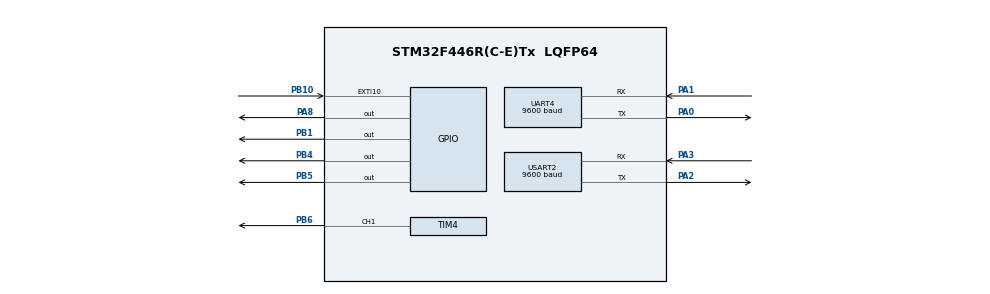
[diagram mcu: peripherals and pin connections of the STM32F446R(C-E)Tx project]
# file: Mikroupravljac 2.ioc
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Mcu.Family=STM32F4
Mcu.Name=STM32F446R(C-E)Tx
Mcu.Package=LQFP64
NVIC.EXTI15_10_IRQn=true\:3\:0\:true\:false\:true\:true\:true\:true
NVIC.PriorityGroup=NVIC_PRIORITYGROUP_4
NVIC.USART2_IRQn=true\:0\:0\:false\:false\:true\:true\:true\:true
PA0-WKUP.Mode=Asynchronous
PA0-WKUP.Signal=UART4_TX
PA1.Mode=Asynchronous
PA1.Signal=UART4_RX
PA13.Mode=Serial_Wire
PA13.Signal=SYS_JTMS-SWDIO
PA14.Mode=Serial_Wire
PA14.Signal=SYS_JTCK-SWCLK
PA2.Mode=Asynchronous
PA2.Signal=USART2_TX
PA3.Mode=Asynchronous
PA3.Signal=USART2_RX
PA8.Signal=GPIO_Output
PB1.Signal=GPIO_Output
PB10.GPIO_ModeDefaultEXTI=GPIO_MODE_IT_FALLING
PB10.GPIO_PuPd=GPIO_PULLUP
PB10.Signal=GPXTI10
PB4.Signal=GPIO_Output
PB5.Signal=GPIO_Output
PB6.Signal=S_TIM4_CH1
ProjectManager.HeapSize=0x200
ProjectManager.StackSize=0x400
ProjectManager.TargetToolchain=STM32CubeIDE
RCC.CortexFreq_Value=16000000
RCC.USBFreq_Value=96000000
RCC.VCOOutputFreq_Value=192000000
SH.S_TIM4_CH1.0=TIM4_CH1,PWM Generation1 CH1
TIM4.Channel-PWM\ Generation1\ CH1=TIM_CHANNEL_1
TIM4.Period=2999
TIM4.Prescaler=15999
TIM4.Pulse-PWM\ Generation1\ CH1=1500
UART4.BaudRate=9600
UART4.VirtualMode=Asynchronous
USART2.BaudRate=9600
USART2.VirtualMode=VM_ASYNC
board=custom

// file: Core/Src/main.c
/* USER CODE BEGIN Header */
/**
  ******************************************************************************
  * @file           : main.c
  * @brief          : Main program body
  ******************************************************************************
  * @attention
  *
  * Copyright (c) 2025 STMicroelectronics.
  * All rights reserved.
  *
  * This software is licensed under terms that can be found in the LICENSE file
  * in the root directory of this software component.
  * If no LICENSE file comes with this software, it is provided AS-IS.
  *
  ******************************************************************************
  */
/* USER CODE END Header */
#include "main.h"
#include "tim.h"
#include "usart.h"
#include "gpio.h"

void SystemClock_Config(void);

int main(void)
{

  /* MCU Configuration--------------------------------------------------------*/

  /* Reset of all peripherals, Initializes the Flash interface and the Systick. */
  HAL_Init();

  /* Configure the system clock */
  SystemClock_Config();

  /* Initialize all configured peripherals */
  MX_GPIO_Init();
  MX_USART2_UART_Init();
  MX_UART4_Init();
  MX_TIM4_Init();
  /* USER CODE BEGIN 2 */
  //int status = 0;
  int status = 0;
  uint8_t msgt = 0x0, msgr = 0x0;
  /* USER CODE END 2 */

  /* Infinite loop */
  /* USER CODE BEGIN WHILE */
  while (1)
  {
	  switch(status) {
	  	  case 0:	//slucaj greske, titrajuce zuto
	  		  __HAL_TIM_SET_COMPARE(&htim4, TIM_CHANNEL_1, 1500);
	  	  	  HAL_TIM_PWM_Start(&htim4, TIM_CHANNEL_1);
	  		  HAL_GPIO_WritePin(GPIOA, GPIO_PIN_8, 0);	//gasenje svega osim zutog
	  		  HAL_GPIO_WritePin(GPIOB, GPIO_PIN_1|GPIO_PIN_4|GPIO_PIN_5, 0);	//^
			  HAL_Delay(3000);
	  		  break;

	  	  case 1:	//Zeleno za aute
	  		  if(msgt!=0x0){
	  	  		  __HAL_TIM_SET_COMPARE(&htim4, TIM_CHANNEL_1, 3000);
	  			  HAL_TIM_PWM_Stop(&htim4, TIM_CHANNEL_1);
	  			  HAL_GPIO_WritePin(GPIOA, GPIO_PIN_8, 1);	//zeleno za aute
	  			  HAL_GPIO_WritePin(GPIOB, GPIO_PIN_5, 1);	//crveno za pješake
	  			  HAL_GPIO_WritePin(GPIOB, GPIO_PIN_1|GPIO_PIN_4, 0);

	  		  }
	  			  break;

	  	  case 2:	//Zeleno za pjesake
	  		  HAL_TIM_PWM_Stop(&htim4, TIM_CHANNEL_1);
	  		  __HAL_TIM_SET_COMPARE(&htim4, TIM_CHANNEL_1, 3000);
	  		  HAL_TIM_PWM_Start(&htim4, TIM_CHANNEL_1);		//upaljeno zuto 3s prije promjene na crveno
	  		  HAL_GPIO_WritePin(GPIOA, GPIO_PIN_8, 0);		//gasi zeleno za aute
			  HAL_Delay(3000);
			  HAL_GPIO_WritePin(GPIOB, GPIO_PIN_5, 0);		//gasi crveno za pjesake
	  		  HAL_GPIO_WritePin(GPIOB, GPIO_PIN_1|GPIO_PIN_4, 1);	//zeleno pjesaci i crveno auti
	  		  HAL_TIM_PWM_Stop(&htim4, TIM_CHANNEL_1);
	  		  HAL_Delay(20000);		//20s za prijelaz pjesaka
	 		  HAL_TIM_PWM_Start(&htim4, TIM_CHANNEL_1);
	 		  HAL_GPIO_WritePin(GPIOB, GPIO_PIN_1, 0);	//gasimo zeleno pjesake
  			  HAL_GPIO_WritePin(GPIOB, GPIO_PIN_5, 1);	//crveno za pjesake
  			  HAL_Delay(3000);		//3s zutog prije promjene
  			  HAL_TIM_PWM_Stop(&htim4, TIM_CHANNEL_1);
	  		  __HAL_TIM_SET_COMPARE(&htim4, TIM_CHANNEL_1, 1500);	//Vracanje PWM Duty cyclea za titranje
	  		  HAL_GPIO_WritePin(GPIOA, GPIO_PIN_8, 1);	//zeleno za aute
	  		  HAL_GPIO_WritePin(GPIOB, GPIO_PIN_1|GPIO_PIN_4, 0);
			  status = 1;
	  		  break;
	  	  }
	  	  msgt = 0x0;
	  	  msgr = 0x4;
	  	  HAL_UART_Receive(&huart4, &msgr, sizeof(msgr), 1000);	//primanje podatka
	  	  HAL_Delay(20);

	  	  if(msgr != 0x0){
	  		 msgt = msgr;
	  		 HAL_UART_Transmit(&huart4, &msgt, sizeof(msgt), 100);	//slanje odgovora
	  		 status = 1;
	  	  }else{
	  		 status = 0;

	  	  }
	  	  if(msgr == 0x6){
	  		  status = 2;
	  	  }

  	  }
}

void SystemClock_Config(void)
{
  RCC_OscInitTypeDef RCC_OscInitStruct = {0};
  RCC_ClkInitTypeDef RCC_ClkInitStruct = {0};

  /** Configure the main internal regulator output voltage
  */
  __HAL_RCC_PWR_CLK_ENABLE();
  __HAL_PWR_VOLTAGESCALING_CONFIG(PWR_REGULATOR_VOLTAGE_SCALE3);

  /** Initializes the RCC Oscillators according to the specified parameters
  * in the RCC_OscInitTypeDef structure.
  */
  RCC_OscInitStruct.OscillatorType = RCC_OSCILLATORTYPE_HSI;
  RCC_OscInitStruct.HSIState = RCC_HSI_ON;
  RCC_OscInitStruct.HSICalibrationValue = RCC_HSICALIBRATION_DEFAULT;
  RCC_OscInitStruct.PLL.PLLState = RCC_PLL_NONE;
  if (HAL_RCC_OscConfig(&RCC_OscInitStruct) != HAL_OK)
  {
    Error_Handler();
  }

  /** Initializes the CPU, AHB and APB buses clocks
  */
  RCC_ClkInitStruct.ClockType = RCC_CLOCKTYPE_HCLK|RCC_CLOCKTYPE_SYSCLK
                              |RCC_CLOCKTYPE_PCLK1|RCC_CLOCKTYPE_PCLK2;
  RCC_ClkInitStruct.SYSCLKSource = RCC_SYSCLKSOURCE_HSI;
  RCC_ClkInitStruct.AHBCLKDivider = RCC_SYSCLK_DIV1;
  RCC_ClkInitStruct.APB1CLKDivider = RCC_HCLK_DIV1;
  RCC_ClkInitStruct.APB2CLKDivider = RCC_HCLK_DIV1;

  if (HAL_RCC_ClockConfig(&RCC_ClkInitStruct, FLASH_LATENCY_0) != HAL_OK)
  {
    Error_Handler();
  }
}

void Error_Handler(void)
{
  __disable_irq();
  while (1)
  {
  }
}
